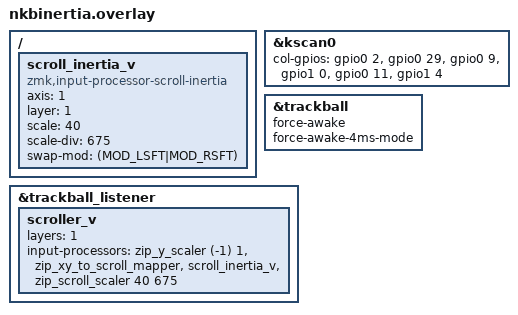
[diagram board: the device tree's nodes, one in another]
/* Inertia scroll test (fork: nlazcani/zmk-input-processor-scroll-inertia on ZMK main).
   Hold key0 -> scroll layer (1): trackball scrolls with iOS-style momentum.
   axis=1 (vertical). Hold Shift while scrolling = horizontal (swap-mod). */
#include "nice_kb.dtsi"
#include <input/processors.dtsi>
#include <dt-bindings/zmk/modifiers.h>

&kscan0 {
    col-gpios
        = <&gpio0  2 (GPIO_ACTIVE_HIGH | GPIO_PULL_DOWN)>
        , <&gpio0 29 (GPIO_ACTIVE_HIGH | GPIO_PULL_DOWN)>
        , <&gpio0  9 (GPIO_ACTIVE_HIGH | GPIO_PULL_DOWN)>
        , <&gpio1  0 (GPIO_ACTIVE_HIGH | GPIO_PULL_DOWN)>
        , <&gpio0 11 (GPIO_ACTIVE_HIGH | GPIO_PULL_DOWN)>
        , <&gpio1  4 (GPIO_ACTIVE_HIGH | GPIO_PULL_DOWN)>
        ;
};

&trackball {
    force-awake;
    force-awake-4ms-mode;
};

/ {
    scroll_inertia_v: scroll_inertia_v {
        compatible = "zmk,input-processor-scroll-inertia";
        #input-processor-cells = <0>;
        axis = <1>;               /* vertical */
        layer = <1>;              /* scroll layer */
        scale = <40>;             /* ~10x sensitivity (was 4) */
        scale-div = <675>;
        swap-mod = <(MOD_LSFT|MOD_RSFT)>;   /* hold shift -> horizontal */
    };
};

&trackball_listener {
    scroller_v {
        layers = <1>;
        input-processors = <
            &zip_y_scaler (-1) 1
            &zip_xy_to_scroll_mapper
            &scroll_inertia_v
            &zip_scroll_scaler 40 675
        >;
    };
};
